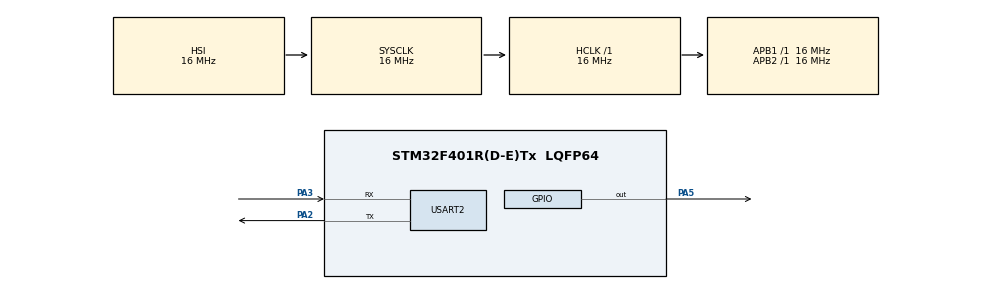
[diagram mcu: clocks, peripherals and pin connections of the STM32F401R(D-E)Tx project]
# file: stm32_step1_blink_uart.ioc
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Mcu.Family=STM32F4
Mcu.Name=STM32F401R(D-E)Tx
Mcu.Package=LQFP64
NVIC.PriorityGroup=NVIC_PRIORITYGROUP_4
PA13.Mode=Serial_Wire
PA13.Signal=SYS_JTMS-SWDIO
PA14.Mode=Serial_Wire
PA14.Signal=SYS_JTCK-SWCLK
PA2.Mode=Asynchronous
PA2.Signal=USART2_TX
PA3.Mode=Asynchronous
PA3.Signal=USART2_RX
PA5.Signal=GPIO_Output
ProjectManager.HeapSize=0x200
ProjectManager.StackSize=0x400
ProjectManager.TargetToolchain=STM32CubeIDE
RCC.AHBFreq_Value=16000000
RCC.APB1Freq_Value=16000000
RCC.APB2Freq_Value=16000000
RCC.CortexFreq_Value=16000000
RCC.HSE_VALUE=25000000
RCC.HSI_VALUE=16000000
RCC.LSE_VALUE=32768
RCC.SYSCLKFreq_VALUE=16000000
RCC.VCOOutputFreq_Value=192000000
USART2.VirtualMode=VM_ASYNC
board=custom

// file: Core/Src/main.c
/* USER CODE BEGIN Header */
/**
  ******************************************************************************
  * @file           : main.c
  * @brief          : STM32 NUCLEO-F401RE rotary encoder bring-up
  *
  * This firmware verifies external sensor interfacing using a mechanical
  * rotary encoder. Encoder channel states are read through GPIO inputs with
  * internal pull-up resistors and streamed over USART2 for debugging.
  *
  ******************************************************************************
  */
/* USER CODE END Header */

#include "main.h"
#include <stdio.h>

#define ENCODER_A_PORT        GPIOB
#define ENCODER_A_PIN         GPIO_PIN_6    /* D10 */

#define ENCODER_B_PORT        GPIOC
#define ENCODER_B_PIN         GPIO_PIN_7    /* D9 */

#define UART_PRINT_PERIOD_MS  200U

UART_HandleTypeDef huart2;

void SystemClock_Config(void);
static void MX_GPIO_Init(void);
static void MX_USART2_UART_Init(void);

/* USER CODE BEGIN PFP */
static void Encoder_PrintRawState(void);
/* USER CODE END PFP */

/* USER CODE BEGIN 0 */
/**
  * @brief Redirect printf() output to USART2.
  */
int __io_putchar(int ch)
{
    HAL_UART_Transmit(&huart2, (uint8_t *)&ch, 1U, HAL_MAX_DELAY);
    return ch;
}

/**
  * @brief Read and print raw rotary encoder channel states.
  *
  * Encoder wiring:
  * - Channel A: D10 / PB6
  * - Channel B: D9  / PC7
  * - Common:    GND
  */
static void Encoder_PrintRawState(void)
{
    uint8_t encoder_a = HAL_GPIO_ReadPin(ENCODER_A_PORT, ENCODER_A_PIN);
    uint8_t encoder_b = HAL_GPIO_ReadPin(ENCODER_B_PORT, ENCODER_B_PIN);

    printf("A=%u B=%u\r\n", encoder_a, encoder_b);
}
/* USER CODE END 0 */

int main(void)
{
    HAL_Init();
    SystemClock_Config();

    MX_GPIO_Init();
    MX_USART2_UART_Init();

    printf("\r\nSTM32 CAN Telemetry Node - Rotary Encoder Bring-up\r\n");

    while (1)
    {
        Encoder_PrintRawState();
        HAL_Delay(UART_PRINT_PERIOD_MS);
    }
}

void SystemClock_Config(void)
{
    RCC_OscInitTypeDef RCC_OscInitStruct = {0};
    RCC_ClkInitTypeDef RCC_ClkInitStruct = {0};

    __HAL_RCC_PWR_CLK_ENABLE();
    __HAL_PWR_VOLTAGESCALING_CONFIG(PWR_REGULATOR_VOLTAGE_SCALE2);

    RCC_OscInitStruct.OscillatorType = RCC_OSCILLATORTYPE_HSI;
    RCC_OscInitStruct.HSIState = RCC_HSI_ON;
    RCC_OscInitStruct.HSICalibrationValue = RCC_HSICALIBRATION_DEFAULT;
    RCC_OscInitStruct.PLL.PLLState = RCC_PLL_NONE;

    if (HAL_RCC_OscConfig(&RCC_OscInitStruct) != HAL_OK)
    {
        Error_Handler();
    }

    RCC_ClkInitStruct.ClockType = RCC_CLOCKTYPE_HCLK |
                                  RCC_CLOCKTYPE_SYSCLK |
                                  RCC_CLOCKTYPE_PCLK1 |
                                  RCC_CLOCKTYPE_PCLK2;

    RCC_ClkInitStruct.SYSCLKSource = RCC_SYSCLKSOURCE_HSI;
    RCC_ClkInitStruct.AHBCLKDivider = RCC_SYSCLK_DIV1;
    RCC_ClkInitStruct.APB1CLKDivider = RCC_HCLK_DIV1;
    RCC_ClkInitStruct.APB2CLKDivider = RCC_HCLK_DIV1;

    if (HAL_RCC_ClockConfig(&RCC_ClkInitStruct, FLASH_LATENCY_0) != HAL_OK)
    {
        Error_Handler();
    }
}

static void MX_USART2_UART_Init(void)
{
    huart2.Instance = USART2;
    huart2.Init.BaudRate = 115200;
    huart2.Init.WordLength = UART_WORDLENGTH_8B;
    huart2.Init.StopBits = UART_STOPBITS_1;
    huart2.Init.Parity = UART_PARITY_NONE;
    huart2.Init.Mode = UART_MODE_TX_RX;
    huart2.Init.HwFlowCtl = UART_HWCONTROL_NONE;
    huart2.Init.OverSampling = UART_OVERSAMPLING_16;

    if (HAL_UART_Init(&huart2) != HAL_OK)
    {
        Error_Handler();
    }
}

static void MX_GPIO_Init(void)
{
    GPIO_InitTypeDef GPIO_InitStruct = {0};

    __HAL_RCC_GPIOA_CLK_ENABLE();
    __HAL_RCC_GPIOB_CLK_ENABLE();
    __HAL_RCC_GPIOC_CLK_ENABLE();

    /* Onboard LD2 LED on PA5 */
    HAL_GPIO_WritePin(GPIOA, GPIO_PIN_5, GPIO_PIN_RESET);

    GPIO_InitStruct.Pin = GPIO_PIN_5;
    GPIO_InitStruct.Mode = GPIO_MODE_OUTPUT_PP;
    GPIO_InitStruct.Pull = GPIO_NOPULL;
    GPIO_InitStruct.Speed = GPIO_SPEED_FREQ_LOW;
    HAL_GPIO_Init(GPIOA, &GPIO_InitStruct);

    /* Encoder channel A: PB6 / D10 */
    GPIO_InitStruct.Pin = ENCODER_A_PIN;
    GPIO_InitStruct.Mode = GPIO_MODE_INPUT;
    GPIO_InitStruct.Pull = GPIO_PULLUP;
    HAL_GPIO_Init(ENCODER_A_PORT, &GPIO_InitStruct);

    /* Encoder channel B: PC7 / D9 */
    GPIO_InitStruct.Pin = ENCODER_B_PIN;
    GPIO_InitStruct.Mode = GPIO_MODE_INPUT;
    GPIO_InitStruct.Pull = GPIO_PULLUP;
    HAL_GPIO_Init(ENCODER_B_PORT, &GPIO_InitStruct);
}

void Error_Handler(void)
{
    __disable_irq();

    while (1)
    {
        HAL_GPIO_TogglePin(GPIOA, GPIO_PIN_5);
        HAL_Delay(100U);
    }
}
